# STM32WBA54 register map
File version: 1.0
CPU: CM33 r0p1, little endian, MPU, FPU, 4 interrupt priority bits
Registers are 32-bit, read-write, reset 0x0 unless marked. A register's access mark holds for its fields unless they carry their own. Offsets are from the block's base; [hi:lo] are bit positions.

## SYSCFG — System configuration controller
Base 0x46000400
Same registers: SEC_SYSCFG 0x56000400
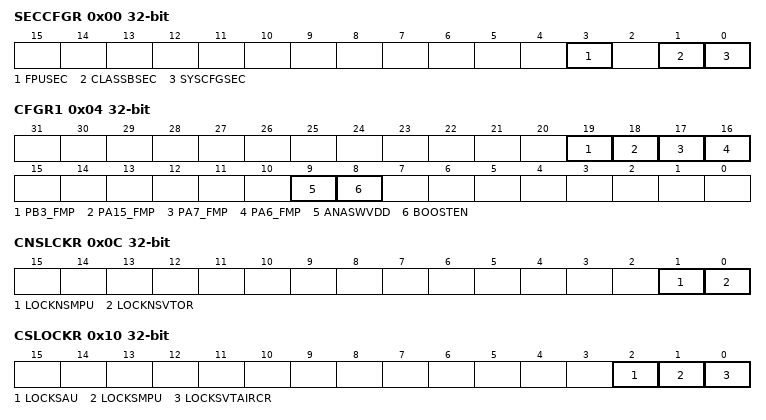
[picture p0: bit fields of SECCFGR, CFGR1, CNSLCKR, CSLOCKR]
0x00 SECCFGR — SYSCFG secure configuration register
  [3] FPUSEC — FPU security
  [1] CLASSBSEC — Class B security
  [0] SYSCFGSEC — SYSCFG clock control, memory erase status and compensation cell registers security
0x04 CFGR1 — SYSCFG configuration register 1
  [19] PB3_FMP — Fast-mode Plus drive capability activation on PB3 This bit can be read and written only with secure access if PB3 is secure in GPIOB. This bit enables the Fast-mode Plus drive mode for PB3 when PB3 is not used by I2C peripheral. This can be used to dive a LED for instance. Access can be protected by GPIOB SEC3.
  [18] PA15_FMP — Fast-mode Plus drive capability activation on PA15 This bit can be read and written only with secure access if PA15 is secure in GPIOA. This bit enables the Fast-mode Plus drive mode for PA15 when PA15 is not used by I2C peripheral. This can be used to dive a LED for instance. Access can be protected by GPIOA SEC15.
  [17] PA7_FMP — Fast-mode Plus drive capability activation on PA7 This bit can be read and written only with secure access if PA7 is secure in GPIOA. This bit enables the Fast-mode Plus drive mode for PA7 when PA7 is not used by I2C peripheral. This can be used to dive a LED for instance. Access can be protected by GPIOA SEC7.
  [16] PA6_FMP — Fast-mode Plus drive capability activation on PA6 This bit can be read and written only with secure access if PA6 is secure in GPIOA. This bit enables the Fast-mode Plus drive mode for PA6 when PA6 is not used by I2C peripheral. This can be used to dive a LED for instance. Access can be protected by GPIOA SEC6.
  [9] ANASWVDD — GPIO analog switch control voltage selection Access can be protected by GTZC_TZSC ADC4SEC. Note: Refer to Table121 for setting.
  [8] BOOSTEN — I/O analog switch voltage booster enable Access can be protected by GTZC_TZSC ADC4SEC. Note: Refer to Table121 for setting.
0x08 FPUIMR reset 0x3F — SYSCFG FPU interrupt mask register
  [5:0] FPU_IE — Floating point unit interrupts enable bits FPU_IE[5]: Inexact interrupt enable (interrupt disable at reset) FPU_IE[4]: Input abnormal interrupt enable FPU_IE[3]: Overflow interrupt enable FPU_IE[2]: Underflow interrupt enable FPU_IE[1]: Divide-by-zero interrupt enable FPU_IE[0]: Invalid operation Interrupt enable
0x0C CNSLCKR — SYSCFG CPU non-secure lock register
  [1] LOCKNSMPU — Non-secure MPU registers lock This bit is set by software and cleared only by a system reset. When set, this bit disables write access to non-secure MPU_CTRL_NS, MPU_RNR_NS and MPU_RBAR_NS registers.
  [0] LOCKNSVTOR — VTOR_NS register lock This bit is set by software and cleared only by a system reset.
0x10 CSLOCKR — SYSCFG CPU secure lock register
  [2] LOCKSAU — SAU registers lock This bit is set by software and cleared only by a system reset. When set, it disables write access to SAU_CTRL, SAU_RNR, SAU_RBAR and SAU_RLAR registers.
  [1] LOCKSMPU — Secure MPU registers lock This bit is set by software and cleared only by a system reset. When set, it disables write access to secure MPU_CTRL, MPU_RNR and MPU_RBAR registers.
  [0] LOCKSVTAIRCR — VTOR_S register and AIRCR register bits lock This bit is set by software and cleared only by a system reset. When set, it disables write access to VTOR_S register, PRIS and BFHFNMINS bits in the AIRCR register.
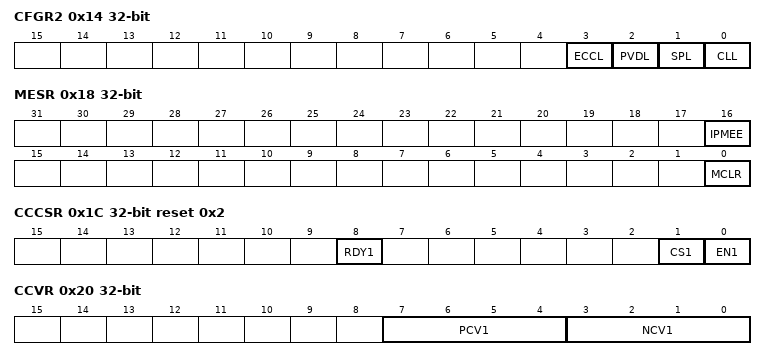
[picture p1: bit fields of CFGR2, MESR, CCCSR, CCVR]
0x14 CFGR2 — SYSCFG configuration register 2
  [3] ECCL — ECC lock This bit is set by software and cleared only by a system reset. It can be used to enable and lock the Flash ECC double error signal connection to TIM1/16/17 break input.
  [2] PVDL — PVD lock enable bit This bit is set by software and cleared only by a system reset. It can be used to enable and lock the PVD connection to TIM1/16/17 break input, as well as the PVDE and PVDLS[2:0] in the PWR register.
  [1] SPL — SRAM2 parity lock bit This bit is set by software and cleared only by a system reset. It can be used to enable and lock the SRAM2 parity error signal connection to TIM1/16/17 break inputs.
  [0] CLL — Cortex-M33 LOCKUP (hardfault) output enable This bit is set by software and cleared only by a system reset. It can be used to enable and lock the connection of Cortex-M33 LOCKUP (hardfault) output to TIM1/16/17 break input.
0x18 MESR — SYSCFG memory erase status register
  [16] IPMEE — ICACHE and PKA SRAM erase status This bit is set by hardware when ICACHE and PKA SRAM erase is completed after potential tamper detection (refer to Section75: Tamper and backup registers (TAMP) for more details). This bit is cleared by software by writing 1 to it.
  [0] MCLR — Device memories erase status This bit is set by hardware when SRAM2, ICACHE, PKA SRAM erase is completed after power-on reset or tamper detection (refer to Section75: Tamper and backup registers (TAMP) for more details). This bit is not reset by system reset and is cleared by software by writing 1 to it.
0x1C CCCSR access per field reset 0x2 — SYSCFG compensation cell control/status register
  [8] RDY1 ro — VDD I/Os compensation cell ready flag This bit provides the compensation cell status of the I/Os supplied by VsubDD/sub. Note: The HSI16 clock is required for the compensation cell to work properly. The compensation cell ready bit (RDY1) is not set if the HSI16 clock is not enabled (HSION).
  [1] CS1 rw — VDD I/Os code selection This bit selects the code to be applied for the compensation cell of the I/Os supplied by VsubDD/sub.
  [0] EN1 rw — VDD I/Os compensation cell enable This bit enables the compensation cell of the I/Os supplied by VsubDD/sub.
0x20 CCVR ro — SYSCFG compensation cell value register
  [7:4] PCV1 — PMOS compensation value of the I/Os supplied by VsubDD/sub This value is provided by the cell and can be used by the CPU to compute an I/Os compensation cell code for PMOS transistors. This code is applied to the I/Os compensation cell when the CS1 bit of the SYSCFG_CCCSR is reset.
  [3:0] NCV1 — NMOS compensation value of the I/Os supplied by VsubDD/sub This value is provided by the cell and can be used by the CPU to compute an I/Os compensation cell code for NMOS transistors. This code is applied to the I/Os compensation cell when the CS1 bit of the SYSCFG_CCCSR is reset.
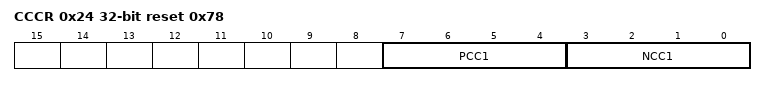
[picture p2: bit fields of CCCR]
0x24 CCCR reset 0x78 — SYSCFG compensation cell code register
  [7:4] PCC1 — PMOS compensation code of the I/Os supplied by VsubDD/sub These bits are written by software to define an I/Os compensation cell code for PMOS transistors. This code is applied to the I/Os compensation cell when the CS1 bit of the SYSCFG_CCCSR is set.
  [3:0] NCC1 — NMOS compensation code of the I/Os supplied by VsubDD/sub These bits are written by software to define an I/Os compensation cell code for NMOS transistors. This code is applied to the I/Os compensation cell when the CS1 bit of the SYSCFG_CCCSR is set.
0x2C RSSCMDR — SYSCFG RSS command register
  [15:0] RSSCMD — RSS commands This field defines a command to be executed by the RSS.
